# PN73xxAU register map
File version: 2
CPU: CM0 r0p0, little endian, no MPU, no FPU, 2 interrupt priority bits
Registers are 32-bit, read-write, reset 0x0 unless marked. A register's access mark holds for its fields unless they carry their own. Offsets are from the block's base; [hi:lo] are bit positions; {n}, {i} and the like mark numbered series.

## Timer — General purpose timer 0/1/2/3
Base 0x4001C000
0x00 TIMERS_TIMER0_CONTROL_REG — Control of Timer 0
  [0] TIMER0_MODE — 0 - single shot 1 - free-running
0x04 TIMERS_TIMER0_TIMEOUT_REG — Timeout value of Timer0
  [11:0] TIMER0_TIMEOUT — Initial count value of Timer0. If set to 0, this feature is disabled.
0x08 TIMERS_TIMER0_COUNT_REG ro — Current count value of Timer0
  [11:0] TIMER0_COUNT — Current count value of Timer0.
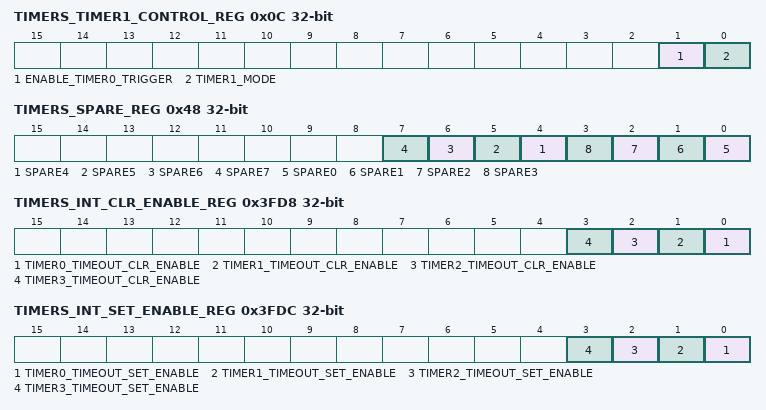
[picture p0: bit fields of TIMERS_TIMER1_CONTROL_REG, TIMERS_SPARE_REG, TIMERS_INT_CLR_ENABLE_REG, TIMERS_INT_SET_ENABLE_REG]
0x0C TIMERS_TIMER1_CONTROL_REG — Control of Timer 1
  [1] ENABLE_TIMER0_TRIGGER — 1- Timer1 will start counting automatically when Timer0 reaches its terminal count (assuming that field TIMER1_TIMEOUT is non-zero in register TIMERS_TIMER1_TIMEOUT)
  [0] TIMER1_MODE — 0 - single shot 1 - free-running
0x10 TIMERS_TIMER1_TIMEOUT_REG — Timeout value of Timer1
  [11:0] TIMER1_TIMEOUT — Initial count value of Timer1. If set to 0, this feature is disabled.
0x14 TIMERS_TIMER1_COUNT_REG ro — Current count value of Timer1
  [11:0] TIMER1_COUNT — Current count value of Timer1.
0x18 TIMERS_TIMER2_CONTROL_REG — Control of Timer 2
  [0] TIMER2_MODE — 0 - single shot 1 - free-running
0x1C TIMERS_TIMER2_TIMEOUT_REG — Timeout value of Timer2
  [31:0] TIMER2_TIMEOUT — Initial count value of Timer2. If set to 0, this feature is disabled.
0x20 TIMERS_TIMER2_COUNT_REG ro — Current count value of Timer2
  [31:0] TIMER2_COUNT — Current count value of Timer2.
0x24 TIMERS_TIMER3_CONTROL_REG — Control of Timer 3
  [0] TIMER3_MODE — 0 - single shot 1 - free-running
0x28 TIMERS_TIMER3_TIMEOUT_REG — Timeout value of Timer3
  [31:0] TIMER3_TIMEOUT — Initial count value of Timer3. If set to 0, this feature is disabled.
0x2C TIMERS_TIMER3_COUNT_REG ro — Current count value of Timer3
  [31:0] TIMER3_COUNT — Current count value of Timer3.
0x30 TIMERS_WDOG_CONTROL_REG — Control of Watchdog Timer
  [0] WDOG_KICK wo — 1 - re-initialise the Watchdog Timer to value WDOG_TIMEOUT 0 - no effect
0x34 TIMERS_WDOG_TIMEOUT_REG — Timeout value of Watchdog Timer
  [9:0] WDOG_TIMEOUT — Initial count value of Watchdog Timer. If set to 0, this feature is disabled.
0x38 TIMERS_WDOG_TRIGGER_INT_REG — Count value of Watchdog Timer which triggers interrupt
  [9:0] WDOG_INT_THRESHOLD — Value of count_reg which will trig a watchdog IT
0x3C TIMERS_WDOG_COUNT_REG ro — Current count value of Watchdog Timer
  [9:0] WDOG_COUNT — Current count value of Watchdog Timer.
0x48 TIMERS_SPARE_REG — Timers spare register
  [n] SPARE{n} (n=4..7) — spare{n} read/write
  [n] SPARE{n} ro (n=0..3) — spare{n} read only
0x3FCC TIMERS_WDOG_INT_STATUS_REG ro — Watchdog Interrupt status
  [0] WDOG_TIMEOUT_STATUS — Wdog timeout interrupt status
0x3FD0 TIMERS_WDOG_INT_CLR_STATUS_REG wo — Watchdog clear interrupt enable
  [0] WDOG_TIMEOUT_CLR_STATUS — 1 - clear watchdog timeout interrupt 0 - no effect
0x3FD4 TIMERS_WDOG_INT_SET_STATUS_REG wo — Watchdog set interrupt enable
  [0] WDOG_TIMEOUT_SET_STATUS — 1 - set watchdog timeout interrupt 0 - no effect
0x3FD8 TIMERS_INT_CLR_ENABLE_REG wo — Timer clear interrupt enable
  [n] TIMER{n}_TIMEOUT_CLR_ENABLE (n=0..3) — 1 - clear enable for Timer{n} timeout interrupt 0 - no effect
0x3FDC TIMERS_INT_SET_ENABLE_REG wo — Timer set interrupt enable
  [n] TIMER{n}_TIMEOUT_SET_ENABLE (n=0..3) — 1 - set enable for Timer{n} timeout interrupt 0 - no effect
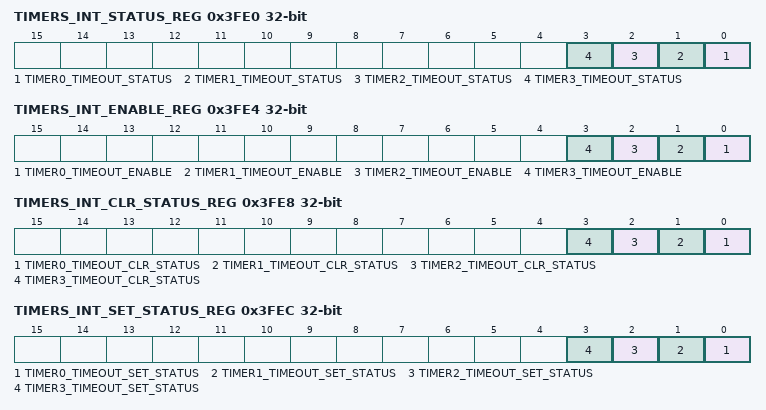
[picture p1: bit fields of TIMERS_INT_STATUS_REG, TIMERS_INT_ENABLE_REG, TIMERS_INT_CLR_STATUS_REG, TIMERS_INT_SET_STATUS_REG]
0x3FE0 TIMERS_INT_STATUS_REG ro — Timer interrupt status
  [n] TIMER{n}_TIMEOUT_STATUS (n=0..3) — Timer{n} timeout interrupt status
0x3FE4 TIMERS_INT_ENABLE_REG ro — Timer interrupt enable
  [n] TIMER{n}_TIMEOUT_ENABLE (n=0..3) — Timer{n} timeout interrupt enable
0x3FE8 TIMERS_INT_CLR_STATUS_REG wo — Timer clear interrupt enable
  [n] TIMER{n}_TIMEOUT_CLR_STATUS (n=0..3) — 1 - clear Timer{n} timeout interrupt 0 - no effect
0x3FEC TIMERS_INT_SET_STATUS_REG wo — Timer set interrupt enable
  [n] TIMER{n}_TIMEOUT_SET_STATUS (n=0..3) — 1 - set Timer{n} timeout interrupt 0 - no effect
